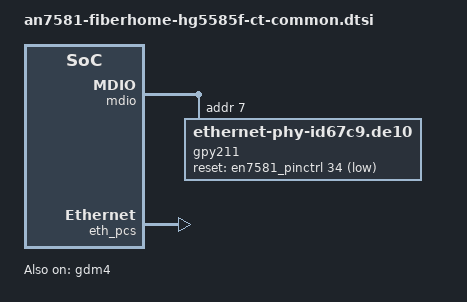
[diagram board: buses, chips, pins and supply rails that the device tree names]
// SPDX-License-Identifier: (GPL-2.0-only OR BSD-2-Clause)
/dts-v1/;

#include "an7581-fiberhome-hg5585f-common.dtsi"

&mdio {
	/*
	 * The explicit GPY211C ID lets phylib register GPIO34 before the first
	 * MDIO transaction, so warm boots cannot probe the PHY while it is reset.
	 */
	gpy211: ethernet-phy@7 {
		compatible = "ethernet-phy-id67c9.de10";
		reg = <7>;
		reset-gpios = <&en7581_pinctrl 34 GPIO_ACTIVE_LOW>;
		reset-assert-us = <100000>;
		reset-deassert-us = <100000>;
	};
};

&eth_pcs {
	status = "okay";
};

&gdm4 {
	nvmem-cells = <&fiberhome_base_mac 0>;
	nvmem-cell-names = "mac-address";
	status = "okay";
	phy-handle = <&gpy211>;
	phy-mode = "2500base-x";
	openwrt,netdev-name = "lan1";
};
